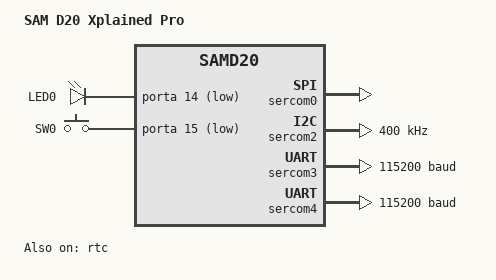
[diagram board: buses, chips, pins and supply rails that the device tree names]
/*
 * Copyright (c) 2018 Sean Nyekjaer
 *
 * SPDX-License-Identifier: Apache-2.0
 */

/dts-v1/;
#include <atmel/samd20.dtsi>

/ {
	model = "SAM D20 Xplained Pro";
	compatible = "atsamd20,xpro", "atmel,samd20j18", "atmel,samd20";

	aliases {
		led0 = &yellow_led;
		sw0 = &user_button;
		i2c-0 = &sercom2;
	};

	chosen {
		zephyr,console = &sercom3;
		zephyr,shell-uart = &sercom3;
		zephyr,sram = &sram0;
		zephyr,flash = &flash0;
	};

	leds {
		compatible = "gpio-leds";
		yellow_led: led_0 {
			gpios = <&porta 14 GPIO_ACTIVE_LOW>;
			label = "LED0";
		};
	};

	buttons {
		compatible = "gpio-keys";
		user_button: button_0 {
			gpios = <&porta 15 (GPIO_PULL_UP | GPIO_ACTIVE_LOW)>;
			label = "SW0";
		};
	};
};

&cpu0 {
	clock-frequency = <48000000>;
};

&sercom0 {
	status = "okay";
	compatible = "atmel,sam0-spi";
	dipo = <0>;
	dopo = <1>;
	#address-cells = <1>;
	#size-cells = <0>;
	cs-gpios = <&porta 5 GPIO_ACTIVE_LOW>;
};

&sercom2 {
	status = "okay";
	compatible = "atmel,sam0-i2c";
	clock-frequency = <I2C_BITRATE_FAST>;
	#address-cells = <1>;
	#size-cells = <0>;
};

&sercom3 {
	status = "okay";
	compatible = "atmel,sam0-uart";
	current-speed = <115200>;
	rxpo = <3>;
	txpo = <1>;
};

&sercom4 {
	status = "okay";
	compatible = "atmel,sam0-uart";
	current-speed = <115200>;
	rxpo = <1>;
	txpo = <0>;
};

&flash0 {
	partitions {
		compatible = "fixed-partitions";
		#address-cells = <1>;
		#size-cells = <1>;

		/*
		 * The final 16 KiB is reserved for the application.
		 * Storage partition will be used by FCB/LittleFS/NVS
		 * if enabled.
		 */
		storage_partition: partition@3c000 {
			label = "storage";
			reg = <0x0003c000 0x00004000>;
		};
	};
};

&rtc {
	status = "okay";
};
